# MB9BF16xx register map
File version: 1.0
Registers are 8-bit, read-write, reset 0x0 unless marked. A register's access mark holds for its fields unless they carry their own. Offsets are from the block's base; [hi:lo] are bit positions; {n}, {i} and the like mark numbered series.

## MFT_PPG — peripheral MFT_PPG
Base 0x40024000
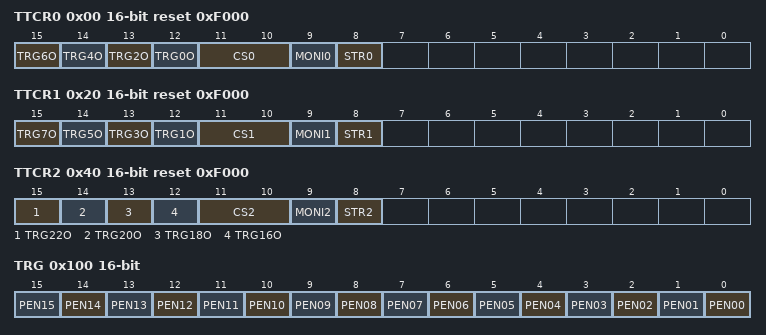
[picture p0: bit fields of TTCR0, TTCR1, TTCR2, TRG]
0x00 TTCR0 16-bit reset 0xF000
  [15] TRG6O, [14] TRG4O, [13] TRG2O, [12] TRG0O, [11:10] CS0, [9] MONI0 ro, [8] STR0
0x08 COMP0 16-bit (reset mask 0xFF00)
0x0C COMP2
0x10 COMP4 16-bit (reset mask 0xFF00)
0x14 COMP6
0x20 TTCR1 16-bit reset 0xF000
  [15] TRG7O, [14] TRG5O, [13] TRG3O, [12] TRG1O, [11:10] CS1, [9] MONI1 ro, [8] STR1
0x28 COMP1 16-bit (reset mask 0xFF00)
0x2C COMP3
0x30 COMP5 16-bit (reset mask 0xFF00)
0x34 COMP7
0x40 TTCR2 16-bit reset 0xF000
  [15] TRG22O, [14] TRG20O, [13] TRG18O, [12] TRG16O, [11:10] CS2, [9] MONI2 ro, [8] STR2
0x48 COMP8 16-bit (reset mask 0xFF00)
0x4C COMP10
0x50 COMP12 16-bit (reset mask 0xFF00)
0x54 COMP14
0x100 TRG 16-bit
  [n] PEN{n:02} (n=0..15)
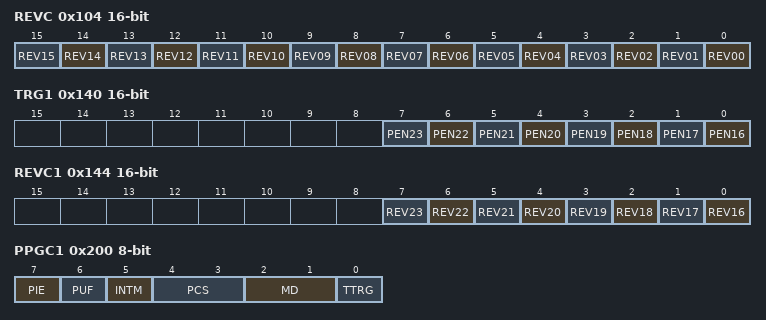
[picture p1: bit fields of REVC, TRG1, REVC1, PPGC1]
0x104 REVC 16-bit
  [n] REV{n:02} (n=0..15)
0x140 TRG1 16-bit
  [n-16] PEN{n} (n=16..23)
0x144 REVC1 16-bit
  [n-16] REV{n} (n=16..23)
0x200 PPGC1
  [7] PIE, [6] PUF, [5] INTM, [4:3] PCS, [2:1] MD, [0] TTRG
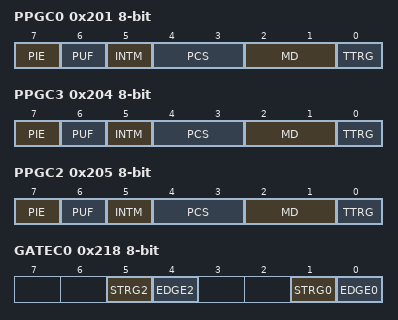
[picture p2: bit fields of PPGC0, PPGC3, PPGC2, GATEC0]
0x201 PPGC0
  [7] PIE, [6] PUF, [5] INTM, [4:3] PCS, [2:1] MD, [0] TTRG
0x204 PPGC3
  [7] PIE, [6] PUF, [5] INTM, [4:3] PCS, [2:1] MD, [0] TTRG
0x205 PPGC2
  [7] PIE, [6] PUF, [5] INTM, [4:3] PCS, [2:1] MD, [0] TTRG
{0x208+4i} PRLL{i} reset not defined (i=0..3)
  [7:0] PRLL
{0x209+4i} PRLH{i} reset not defined (i=0..3)
  [7:0] PRLH
0x218 GATEC0
  [5] STRG2, [4] EDGE2, [1] STRG0, [0] EDGE0
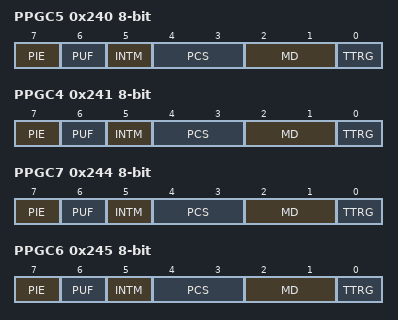
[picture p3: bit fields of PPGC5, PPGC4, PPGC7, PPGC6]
0x240 PPGC5
  [7] PIE, [6] PUF, [5] INTM, [4:3] PCS, [2:1] MD, [0] TTRG
0x241 PPGC4
  [7] PIE, [6] PUF, [5] INTM, [4:3] PCS, [2:1] MD, [0] TTRG
0x244 PPGC7
  [7] PIE, [6] PUF, [5] INTM, [4:3] PCS, [2:1] MD, [0] TTRG
0x245 PPGC6
  [7] PIE, [6] PUF, [5] INTM, [4:3] PCS, [2:1] MD, [0] TTRG
{0x238+4i} PRLL{i} reset not defined (i=4..7)
  [7:0] PRLL
{0x239+4i} PRLH{i} reset not defined (i=4..7)
  [7:0] PRLH
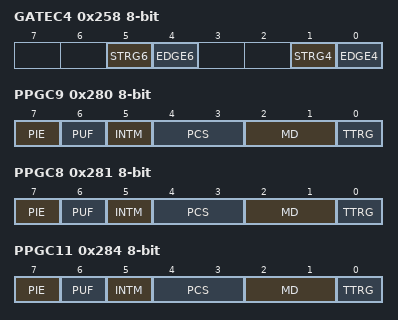
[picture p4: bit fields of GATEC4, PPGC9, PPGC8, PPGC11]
0x258 GATEC4
  [5] STRG6, [4] EDGE6, [1] STRG4, [0] EDGE4
0x280 PPGC9
  [7] PIE, [6] PUF, [5] INTM, [4:3] PCS, [2:1] MD, [0] TTRG
0x281 PPGC8
  [7] PIE, [6] PUF, [5] INTM, [4:3] PCS, [2:1] MD, [0] TTRG
0x284 PPGC11
  [7] PIE, [6] PUF, [5] INTM, [4:3] PCS, [2:1] MD, [0] TTRG
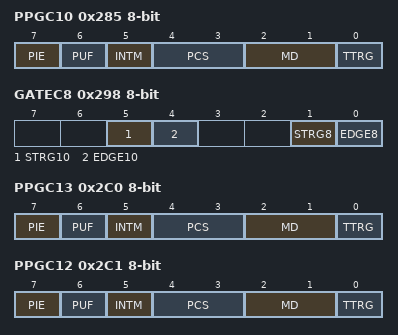
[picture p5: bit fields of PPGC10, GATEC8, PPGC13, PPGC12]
0x285 PPGC10
  [7] PIE, [6] PUF, [5] INTM, [4:3] PCS, [2:1] MD, [0] TTRG
{0x268+4i} PRLL{i} reset not defined (i=8..11)
  [7:0] PRLL
{0x269+4i} PRLH{i} reset not defined (i=8..11)
  [7:0] PRLH
0x298 GATEC8
  [5] STRG10, [4] EDGE10, [1] STRG8, [0] EDGE8
0x2C0 PPGC13
  [7] PIE, [6] PUF, [5] INTM, [4:3] PCS, [2:1] MD, [0] TTRG
0x2C1 PPGC12
  [7] PIE, [6] PUF, [5] INTM, [4:3] PCS, [2:1] MD, [0] TTRG
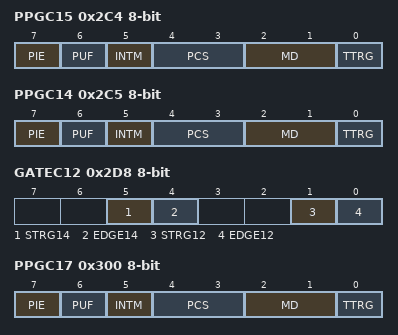
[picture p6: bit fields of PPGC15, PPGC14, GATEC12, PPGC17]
0x2C4 PPGC15
  [7] PIE, [6] PUF, [5] INTM, [4:3] PCS, [2:1] MD, [0] TTRG
0x2C5 PPGC14
  [7] PIE, [6] PUF, [5] INTM, [4:3] PCS, [2:1] MD, [0] TTRG
{0x298+4i} PRLL{i} reset not defined (i=12..15)
  [7:0] PRLL
{0x299+4i} PRLH{i} reset not defined (i=12..15)
  [7:0] PRLH
0x2D8 GATEC12
  [5] STRG14, [4] EDGE14, [1] STRG12, [0] EDGE12
0x300 PPGC17
  [7] PIE, [6] PUF, [5] INTM, [4:3] PCS, [2:1] MD, [0] TTRG
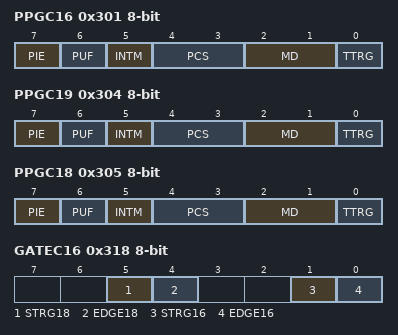
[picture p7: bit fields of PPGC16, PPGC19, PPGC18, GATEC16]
0x301 PPGC16
  [7] PIE, [6] PUF, [5] INTM, [4:3] PCS, [2:1] MD, [0] TTRG
0x304 PPGC19
  [7] PIE, [6] PUF, [5] INTM, [4:3] PCS, [2:1] MD, [0] TTRG
0x305 PPGC18
  [7] PIE, [6] PUF, [5] INTM, [4:3] PCS, [2:1] MD, [0] TTRG
{0x2C8+4i} PRLL{i} reset not defined (i=16..19)
  [7:0] PRLL
{0x2C9+4i} PRLH{i} reset not defined (i=16..19)
  [7:0] PRLH
0x318 GATEC16
  [5] STRG18, [4] EDGE18, [1] STRG16, [0] EDGE16
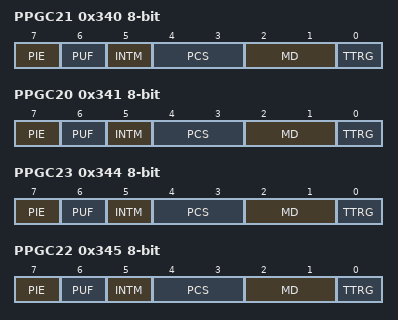
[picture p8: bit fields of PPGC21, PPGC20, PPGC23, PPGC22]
0x340 PPGC21
  [7] PIE, [6] PUF, [5] INTM, [4:3] PCS, [2:1] MD, [0] TTRG
0x341 PPGC20
  [7] PIE, [6] PUF, [5] INTM, [4:3] PCS, [2:1] MD, [0] TTRG
0x344 PPGC23
  [7] PIE, [6] PUF, [5] INTM, [4:3] PCS, [2:1] MD, [0] TTRG
0x345 PPGC22
  [7] PIE, [6] PUF, [5] INTM, [4:3] PCS, [2:1] MD, [0] TTRG
{0x2F8+4i} PRLL{i} reset not defined (i=20..23)
  [7:0] PRLL
{0x2F9+4i} PRLH{i} reset not defined (i=20..23)
  [7:0] PRLH
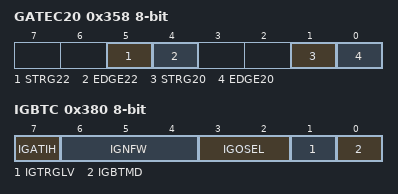
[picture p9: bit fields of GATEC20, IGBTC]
0x358 GATEC20
  [5] STRG22, [4] EDGE22, [1] STRG20, [0] EDGE20
0x380 IGBTC
  [7] IGATIH, [6:4] IGNFW, [3:2] IGOSEL, [1] IGTRGLV, [0] IGBTMD

## Notices in the file
Licence Terms
FUJITSU SEMICONDUCTOR LIMITED (gLICENSORh) hereby grants and
you (gLICENSEEh) hereby accept a non transferable, non-exclusive
licence to use and copy the deliverables (gDeliverablesh) solely for
the purpose of; (i) developing LICENSEEfs development tools and
distributing such development tools to third parties; (ii) generating
derivative representations of the Deliverables to develop and debug
software for LICENSORfs targeted devices or device series identified
within the Deliverables, (together the gPurposeh) under the following
terms and conditions:
1. Ownership.
The Deliverables are the property of LICENSOR. LICENSEE acquires no
right, title or interest in the Deliverables other than the licence
rights granted herein.
2. Use.
LICENSEE shall only be permitted to use the Deliverables for the
Purpose. LICENSEE shall not reverse engineer, decompile or
disassemble the Deliverables, in whole or in part.
3. Copies.
All copies of the Deliverables must bear the same notice(s) contained
on the original copies of the Deliverables.
4. No Warranty.
THE DELIVERABLES ARE PROVIDED gAS ISh AND ANY EXPRESS, IMPLIED OR
STATUTORY WARRANTIES, INCLUDING, BUT NOT LIMITED TO, THE IMPLIED
WARRANTIES OF MERCHANTABILITY, SATISFACTORY QUALITY AND FITNESS FOR
A PARTICULAR PURPOSE ARE DISCLAIMED.
IN NO EVENT SHALL LICENSOR BE LIABLE FOR ANY DIRECT, INDIRECT,
INCIDENTAL, SPECIAL, EXEMPLARY, OR CONSEQUENTIAL DAMAGES HOWEVER CAUSED
AND ON ANY THEORY OF LIABILITY, WHETHER IN CONTRACT, STRICT LIABILITY,
OR TORT (INCLUDING NEGLIGENCE OR OTHERWISE) ARISING IN ANY WAY OUT OF
THE USE OF THE DELIVERABLES, EVEN IF ADVISED OF THE POSSIBILITY OF SUCH
DAMAGE.
LICENSEE EXPRESSLY ASSUMES ALL LIABILITIES AND RISKS, FOR USE OR
OPERATION OF THE DELIVERABLES.
5.In the event that LICENSEE receives early access to the Deliverables,
LICENSEE acknowledges and agrees that;
(a) notwithstanding the licence grants above, LICENSEE shall only be
permitted to use the Deliverables solely internally for evaluation and
providing feedback to LICENSOR;
(b) except with respect to the limited licence grants in 5(a), LICENSEE
shall be subject to all of the terms and conditions set out above; and
(c) the Deliverables are confidential information and LICENSEE shall
maintain in confidence the Deliverables and apply security measures no
less stringent than the measures that LICENSEE applies to its own like
information, but not less than a reasonable degree of care, to prevent
unauthorised disclosure and use of the Deliverables.
